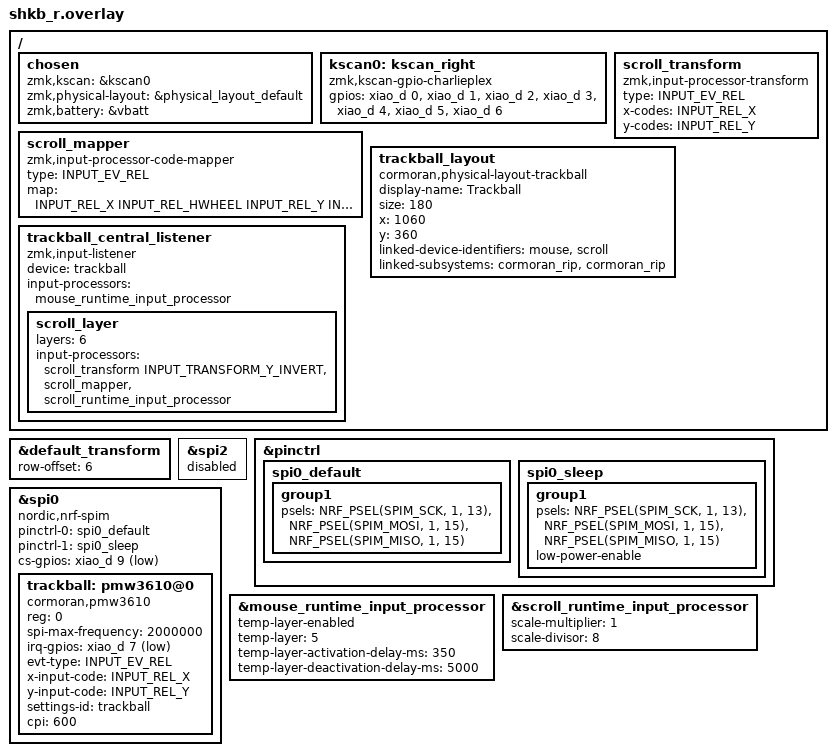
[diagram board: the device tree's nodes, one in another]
#include "shkb.dtsi"
/* shkb.dtsi の RC(row,col) 展開が終わった後に include する
 * （runtime-input-processor.dtsi は keys.h 経由で RC と衝突するマクロを持ち込むため） */
#include <input/processors/runtime-input-processor.dtsi>
#include <dt-bindings/input/input-event-codes.h>
#include <dt-bindings/zmk/input_transform.h>

/ {
    chosen {
        zmk,kscan = &kscan0;
        zmk,physical-layout = &physical_layout_default;
        zmk,battery = &vbatt;
    };

    kscan0: kscan_right {
        compatible = "zmk,kscan-gpio-charlieplex";
        gpios
            = <&xiao_d 0 0>
            , <&xiao_d 1 0>
            , <&xiao_d 2 0>
            , <&xiao_d 3 0>
            , <&xiao_d 4 0>
            , <&xiao_d 5 0>
            , <&xiao_d 6 0>
            ;
    };

    /* オートマウス（トラックボールを動かすと Mouse レイヤーへ）は DYA Studio で
     * 調整できる runtime input processor の一時レイヤー機能に置き換えた。
     * 初期値は旧 zmk,input-processor-temp-layer（Layer 5 / 5000ms）に合わせている。
     * 旧設定の require-prior-idle-ms / excluded-positions に相当する項目は無く、
     * 一時レイヤー上で &trans のキーを押すと解除、&mkp などは維持される。 */

    scroll_transform: scroll_transform {
        compatible = "zmk,input-processor-transform";
        #input-processor-cells = <1>;
        type = <INPUT_EV_REL>;
        x-codes = <INPUT_REL_X>;
        y-codes = <INPUT_REL_Y>;
    };

    scroll_mapper: scroll_mapper {
        compatible = "zmk,input-processor-code-mapper";
        #input-processor-cells = <0>;
        type = <INPUT_EV_REL>;
        map = <INPUT_REL_X INPUT_REL_HWHEEL
               INPUT_REL_Y INPUT_REL_WHEEL>;
    };

    /* DYA Studio のキーマップ表示にトラックボールを描く（見た目のみ）。
     * 座標は physical_layout_default と同じ単位。右手親指の RALT と RGUI の間。 */
    trackball_layout: trackball_layout {
        compatible = "cormoran,physical-layout-trackball";
        display-name = "Trackball";
        size = <180>;
        x = <1060>;
        y = <360>;
        linked-device-identifiers = "mouse", "scroll";
        linked-subsystems = "cormoran_rip", "cormoran_rip";
    };

    /* Right half is the split central and hosts the trackball directly, so
     * events are consumed locally instead of relaying over the
     * peripheral->central BLE hop (see shkb_l.overlay). */
    trackball_central_listener: trackball_central_listener {
        compatible = "zmk,input-listener";
        device = <&trackball>;
        input-processors = <&mouse_runtime_input_processor>;

        /* スクロール量（旧 scaler 1/8）は scroll_runtime_input_processor で Studio から調整できる */
        scroll_layer {
            layers = <6>;
            input-processors = <&scroll_transform INPUT_TRANSFORM_Y_INVERT>,
                               <&scroll_mapper>,
                               <&scroll_runtime_input_processor>;
        };
    };
};

/* Right half has no split relay to feed in normal mode – the trackball is
 * consumed locally by trackball_central_listener above. */
/delete-node/ &trackball_peripheral_split;

/* Shift right-half kscan rows by 6 to avoid lookup table collision with
 * the left side, which uses rows 0-5. Right charlieplex pins 0-6
 * (rows 0-6) map to effective rows 6-12 in the combined transform. */
&default_transform {
    row-offset = <6>;
};

/* spi2 (xiao_spi) uses the same GPIO pins as our spi0 (P1.13, P1.15).
 * Disable spi2 to avoid pinctrl conflict. */
&spi2 { status = "disabled"; };

&pinctrl {
    spi0_default: spi0_default {
        group1 {
            psels = <NRF_PSEL(SPIM_SCK, 1, 13)>,
                    <NRF_PSEL(SPIM_MOSI, 1, 15)>,
                    <NRF_PSEL(SPIM_MISO, 1, 15)>;
        };
    };

    spi0_sleep: spi0_sleep {
        group1 {
            psels = <NRF_PSEL(SPIM_SCK, 1, 13)>,
                    <NRF_PSEL(SPIM_MOSI, 1, 15)>,
                    <NRF_PSEL(SPIM_MISO, 1, 15)>;
            low-power-enable;
        };
    };
};

&spi0 {
    compatible = "nordic,nrf-spim";
    status = "okay";
    pinctrl-0 = <&spi0_default>;
    pinctrl-1 = <&spi0_sleep>;
    pinctrl-names = "default", "sleep";
    cs-gpios = <&xiao_d 9 GPIO_ACTIVE_LOW>;

    /* DYA Studio のトラックボール / 診断タブに対応した cormoran 版ドライバー。
     * X 反転は shkb_r.conf の CONFIG_PMW3610_INVERT_X で指定している。 */
    trackball: pmw3610@0 {
        compatible = "cormoran,pmw3610";
        reg = <0>;
        spi-max-frequency = <2000000>;
        irq-gpios = <&xiao_d 7 GPIO_ACTIVE_LOW>;
        evt-type = <INPUT_EV_REL>;
        x-input-code = <INPUT_REL_X>;
        y-input-code = <INPUT_REL_Y>;
        settings-id = "trackball";

        cpi = <600>;
    };
};

/* ── DYA Studio: runtime input processor の初期値 ─────────────────────────── */
&mouse_runtime_input_processor {
    /* オートマウス: 動かして 350ms で Layer 5 (Mouse)、止めて 5 秒で解除 */
    temp-layer-enabled;
    temp-layer = <5>;
    /* 打鍵直後の誤爆防止（旧 require-prior-idle-ms = 350 相当）。モジュール既定は 100 */
    temp-layer-activation-delay-ms = <350>;
    temp-layer-deactivation-delay-ms = <5000>;
};

&scroll_runtime_input_processor {
    /* 旧 &scroll_scaler 1 8 と同じ量 */
    scale-multiplier = <1>;
    scale-divisor = <8>;
};
